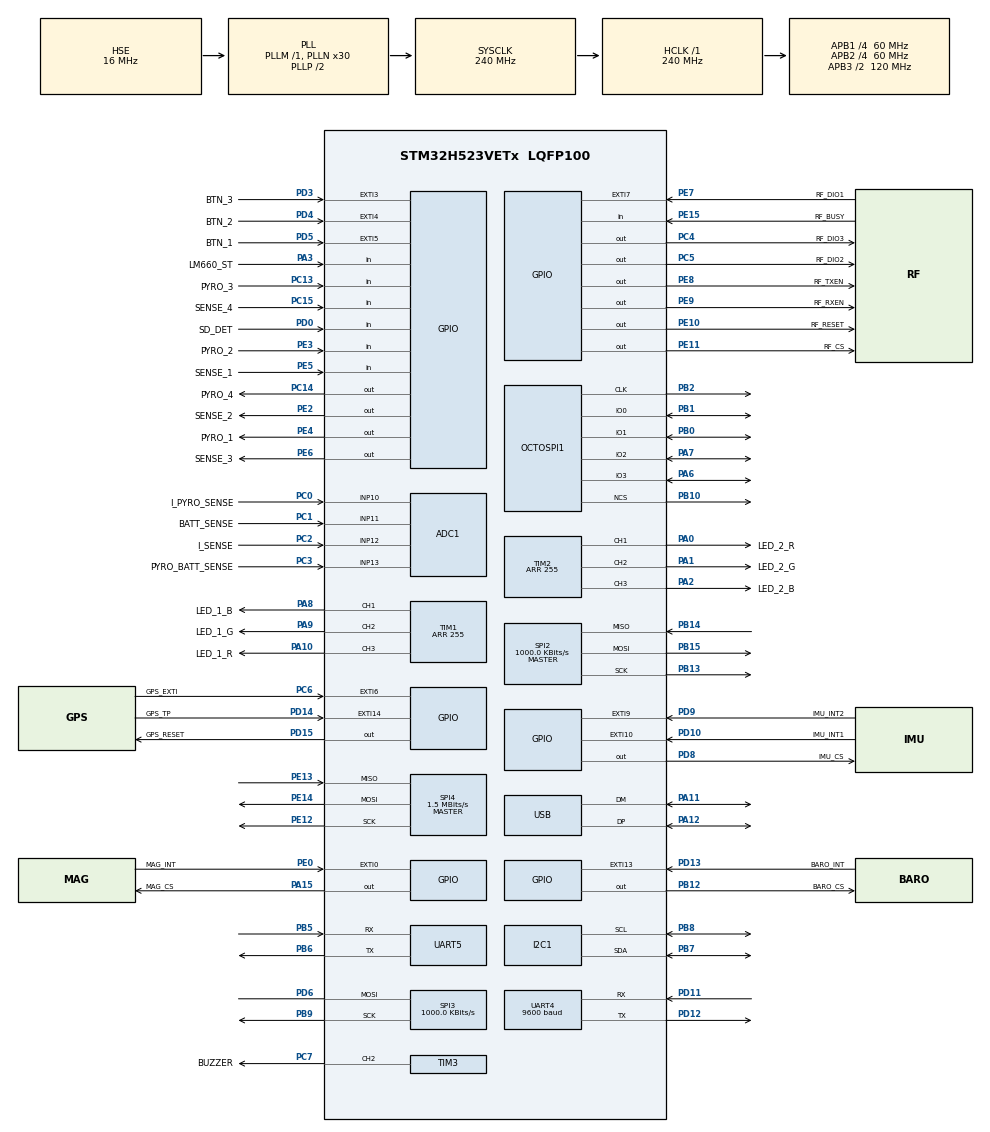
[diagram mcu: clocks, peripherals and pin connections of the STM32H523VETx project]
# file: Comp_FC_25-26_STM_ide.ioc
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ADC1.Channel-1\#ChannelRegularConversion=ADC_CHANNEL_10
ADC1.MonitoredBy-1\#ChannelRegularConversion=__NULL
ADC1.NbrOfConversion=1
ADC1.NbrOfConversionFlag=1
ADC1.OffsetNumber-1\#ChannelRegularConversion=ADC_OFFSET_NONE
ADC1.Rank-1\#ChannelRegularConversion=1
ADC1.SamplingTime-1\#ChannelRegularConversion=ADC_SAMPLETIME_2CYCLES_5
ADC1.master=1
BOOTPATH.BootPathName=LEGACY
BOOTPATH.UserSelectedBootPath=LEGACY
CORTEX_M33_NS.userName=CORTEX_M33
GPDMA1.DESTINC_GPDMACH0=DMA_DINC_INCREMENTED
GPDMA1.DESTINC_GPDMACH4=DMA_DINC_INCREMENTED
GPDMA1.DESTINC_GPDMACH5=DMA_DINC_INCREMENTED
GPDMA1.DIRECTION_GPDMACH1=DMA_MEMORY_TO_PERIPH
GPDMA1.DMAHANDLE_GPDMACH5=hdmatx
GPDMA1.IPHANDLE_GPDMACH0-SIMPLEREQUEST_GPDMACH0=__NULL
GPDMA1.IPHANDLE_GPDMACH1-SIMPLEREQUEST_GPDMACH1=__NULL
GPDMA1.IPHANDLE_GPDMACH4-SIMPLEREQUEST_GPDMACH4=__NULL
GPDMA1.IPHANDLE_GPDMACH5-SIMPLEREQUEST_GPDMACH5=__NULL
GPDMA1.REQUEST_GPDMACH0=GPDMA1_REQUEST_SPI2_RX
GPDMA1.REQUEST_GPDMACH1=GPDMA1_REQUEST_SPI2_TX
GPDMA1.REQUEST_GPDMACH4=GPDMA1_REQUEST_OCTOSPI1
GPDMA1.REQUEST_GPDMACH5=GPDMA1_REQUEST_OCTOSPI1
GPDMA1.SRCINC_GPDMACH1=DMA_SINC_INCREMENTED
GPDMA1.TRANSFERALLOCATEDPORTDEST_GPDMACH0=DMA_DEST_ALLOCATED_PORT1
GPDMA1.TRANSFERALLOCATEDPORTDEST_GPDMACH5=DMA_DEST_ALLOCATED_PORT1
GPDMA1.TRANSFERALLOCATEDPORTSRC_GPDMACH0=DMA_SRC_ALLOCATED_PORT1
GPDMA1.TRANSFERALLOCATEDPORTSRC_GPDMACH4=DMA_SRC_ALLOCATED_PORT1
GPDMA2.CIRCULARMODE_GPDMACH4=DISABLE
GPDMA2.CIRCULARMODE_GPDMACH5=ENABLE
GPDMA2.DESTINC_GPDMACH5=DMA_DINC_INCREMENTED
GPDMA2.DIRECTION_GPDMACH4=DMA_MEMORY_TO_PERIPH
GPDMA2.IPHANDLE_GPDMACH4-SIMPLEREQUEST_GPDMACH4=__NULL
GPDMA2.IPHANDLE_GPDMACH5-SIMPLEREQUEST_GPDMACH5=__NULL
GPDMA2.LINKALLOCATEDPORT_CIRCULAR_GPDMACH5=DMA_LINK_ALLOCATED_PORT1
GPDMA2.REQUEST_GPDMACH4=GPDMA2_REQUEST_UART4_TX
GPDMA2.REQUEST_GPDMACH5=GPDMA2_REQUEST_UART4_RX
GPDMA2.SRCINC_GPDMACH4=DMA_SINC_INCREMENTED
GPDMA2.TRANSFERALLOCATEDPORTDEST_GPDMACH5=DMA_DEST_ALLOCATED_PORT1
GPDMA2.TRANSFERALLOCATEDPORTSRC_GPDMACH5=DMA_SRC_ALLOCATED_PORT1
I2C1.Timing=0x20303E5D
Mcu.Family=STM32H5
Mcu.Name=STM32H523VETx
Mcu.Package=LQFP100
NVIC.EXTI10_IRQn=true\:0\:0\:false\:false\:true\:true\:true\:true
NVIC.EXTI13_IRQn=true\:0\:0\:false\:false\:true\:true\:true\:true
NVIC.EXTI3_IRQn=true\:0\:0\:false\:false\:true\:true\:true\:true
NVIC.EXTI4_IRQn=true\:0\:0\:false\:false\:true\:true\:true\:true
NVIC.EXTI5_IRQn=true\:0\:0\:false\:false\:true\:true\:true\:true
NVIC.EXTI7_IRQn=true\:0\:0\:false\:false\:true\:true\:true\:true
NVIC.EXTI9_IRQn=true\:0\:0\:false\:false\:true\:true\:true\:true
NVIC.GPDMA1_Channel0_IRQn=true\:0\:0\:false\:false\:true\:true\:true\:true
NVIC.GPDMA1_Channel1_IRQn=true\:0\:0\:false\:false\:true\:true\:true\:true
NVIC.GPDMA1_Channel4_IRQn=true\:0\:0\:false\:false\:true\:true\:true\:true
NVIC.GPDMA1_Channel5_IRQn=true\:0\:0\:false\:false\:true\:true\:true\:true
NVIC.GPDMA2_Channel4_IRQn=true\:0\:0\:false\:false\:true\:false\:true\:true
NVIC.GPDMA2_Channel5_IRQn=true\:0\:0\:false\:false\:true\:false\:true\:true
NVIC.PriorityGroup=NVIC_PRIORITYGROUP_4
NVIC.SPI2_IRQn=true\:0\:0\:false\:false\:true\:true\:true\:true
NVIC.SPI3_IRQn=true\:0\:0\:false\:false\:true\:true\:true\:true
NVIC.SPI4_IRQn=true\:0\:0\:false\:false\:true\:true\:true\:true
NVIC.TIM6_IRQn=true\:0\:0\:false\:false\:true\:true\:true\:true
OCTOSPI1.ClockMode=HAL_XSPI_CLOCK_MODE_3
OCTOSPI1.ClockPrescaler=1
OCTOSPI1.MemorySize=HAL_XSPI_SIZE_128MB
PA0.GPIO_Label=LED_2_R
PA0.PinAttribute=Free
PA0.Signal=S_TIM2_CH1
PA1.GPIO_Label=LED_2_G
PA1.PinAttribute=Free
PA1.Signal=S_TIM2_CH2
PA10.GPIO_Label=LED_1_R
PA10.PinAttribute=Free
PA10.Signal=S_TIM1_CH3
PA11.Mode=Device
PA11.Signal=USB_DM
PA12.Mode=Device
PA12.Signal=USB_DP
PA13(JTMS/SWDIO).Mode=Trace_Asynchronous_SW
PA13(JTMS/SWDIO).Signal=DEBUG_JTMS-SWDIO
PA14(JTCK/SWCLK).Mode=Trace_Asynchronous_SW
PA14(JTCK/SWCLK).Signal=DEBUG_JTCK-SWCLK
PA15(JTDI).GPIO_Label=MAG_CS
PA15(JTDI).GPIO_PuPd=GPIO_PULLUP
PA15(JTDI).PinState=GPIO_PIN_RESET
PA15(JTDI).Signal=GPIO_Output
PA2.GPIO_Label=LED_2_B
PA2.PinAttribute=Free
PA2.Signal=S_TIM2_CH3
PA3.GPIO_Label=LM660_ST
PA3.PinAttribute=Free
PA3.Signal=GPIO_Input
PA6.Mode=OCTOSPI1_IO[3\:0]
PA6.PinAttribute=Free
PA6.Signal=OCTOSPI1_IO3
PA7.Mode=OCTOSPI1_IO[3\:0]
PA7.PinAttribute=Free
PA7.Signal=OCTOSPI1_IO2
PA8.GPIO_Label=LED_1_B
PA8.Signal=S_TIM1_CH1
PA9.GPIO_Label=LED_1_G
PA9.PinAttribute=Free
PA9.Signal=S_TIM1_CH2
PB0.Mode=OCTOSPI1_IO[3\:0]
PB0.PinAttribute=Free
PB0.Signal=OCTOSPI1_IO1
PB1.Mode=OCTOSPI1_IO[3\:0]
PB1.PinAttribute=Free
PB1.Signal=OCTOSPI1_IO0
PB10.Mode=quad_mode
PB10.PinAttribute=Free
PB10.Signal=OCTOSPI1_NCS
PB12.GPIO_Label=BARO_CS
PB12.GPIO_PuPd=GPIO_PULLUP
PB12.PinAttribute=Free
PB12.Signal=GPIO_Output
PB13.Mode=Full_Duplex_Master
PB13.PinAttribute=Free
PB13.Signal=SPI2_SCK
PB14.Mode=Full_Duplex_Master
PB14.PinAttribute=Free
PB14.Signal=SPI2_MISO
PB15.Mode=Full_Duplex_Master
PB15.PinAttribute=Free
PB15.Signal=SPI2_MOSI
PB2.Mode=quad_mode
PB2.PinAttribute=Free
PB2.Signal=OCTOSPI1_CLK
PB3(JTDO/TRACESWO).Mode=Trace_Asynchronous_SW
PB3(JTDO/TRACESWO).Signal=DEBUG_JTDO-SWO
PB5.Mode=Asynchronous
PB5.PinAttribute=Free
PB5.Signal=UART5_RX
PB6.Mode=Asynchronous
PB6.PinAttribute=Free
PB6.Signal=UART5_TX
PB7.Mode=I2C
PB7.PinAttribute=Free
PB7.Signal=I2C1_SDA
PB8.Mode=I2C
PB8.PinAttribute=Free
PB8.Signal=I2C1_SCL
PB9.Mode=Simplex_Bidirectional_Master
PB9.PinAttribute=Free
PB9.Signal=SPI3_SCK
PC0.GPIO_Label=I_PYRO_SENSE
PC0.PinAttribute=Free
PC0.Signal=ADCx_INP10
PC1.GPIO_Label=BATT_SENSE
PC1.PinAttribute=Free
PC1.Signal=ADCx_INP11
PC10.PinAttribute=Free
PC10.Signal=SDMMC1_D2
PC11.PinAttribute=Free
PC11.Signal=SDMMC1_D3
PC12.PinAttribute=Free
PC12.Signal=SDMMC1_CK
PC13.GPIO_Label=PYRO_3
PC13.PinAttribute=Free
PC13.Signal=GPIO_Input
PC14-OSC32_IN(OSC32_IN).GPIO_Label=PYRO_4
PC14-OSC32_IN(OSC32_IN).PinAttribute=Free
PC14-OSC32_IN(OSC32_IN).Signal=GPIO_Output
PC15-OSC32_OUT(OSC32_OUT).GPIO_Label=SENSE_4
PC15-OSC32_OUT(OSC32_OUT).PinAttribute=Free
PC15-OSC32_OUT(OSC32_OUT).Signal=GPIO_Input
PC2.GPIO_Label=I_SENSE
PC2.PinAttribute=Free
PC2.Signal=ADCx_INP12
PC3.GPIO_Label=PYRO_BATT_SENSE
PC3.PinAttribute=Free
PC3.Signal=ADCx_INP13
PC4.GPIO_Label=RF_DIO3
PC4.PinAttribute=Free
PC4.Signal=GPIO_Output
PC5.GPIO_Label=RF_DIO2
PC5.PinAttribute=Free
PC5.Signal=GPIO_Output
PC6.GPIO_Label=GPS_EXTI
PC6.PinAttribute=Free
PC6.Signal=GPXTI6
PC7.GPIO_Label=BUZZER
PC7.PinAttribute=Free
PC7.Signal=S_TIM3_CH2
PC8.PinAttribute=Free
PC8.Signal=SDMMC1_D0
PC9.PinAttribute=Free
PC9.Signal=SDMMC1_D1
PD0.GPIO_Label=SD_DET
PD0.PinAttribute=Free
PD0.Signal=GPIO_Input
PD10.GPIO_Label=IMU_INT1
PD10.GPIO_PuPd=GPIO_PULLDOWN
PD10.PinAttribute=Free
PD10.Signal=GPXTI10
PD11.Mode=Asynchronous
PD11.PinAttribute=Free
PD11.Signal=UART4_RX
PD12.Mode=Asynchronous
PD12.PinAttribute=Free
PD12.Signal=UART4_TX
PD13.GPIO_Label=BARO_INT
PD13.GPIO_ModeDefaultEXTI=GPIO_MODE_IT_RISING
PD13.GPIO_PuPd=GPIO_NOPULL
PD13.Signal=GPXTI13
PD14.GPIO_Label=GPS_TP
PD14.PinAttribute=Free
PD14.Signal=GPXTI14
PD15.GPIO_Label=GPS_RESET
PD15.PinAttribute=Free
PD15.Signal=GPIO_Output
PD2.PinAttribute=Free
PD2.Signal=SDMMC1_CMD
PD3.GPIO_Label=BTN_3
PD3.GPIO_PuPd=GPIO_PULLDOWN
PD3.PinAttribute=Free
PD3.Signal=GPXTI3
PD4.GPIO_Label=BTN_2
PD4.GPIO_PuPd=GPIO_PULLDOWN
PD4.PinAttribute=Free
PD4.Signal=GPXTI4
PD5.GPIO_Label=BTN_1
PD5.GPIO_PuPd=GPIO_PULLDOWN
PD5.PinAttribute=Free
PD5.Signal=GPXTI5
PD6.Mode=Simplex_Bidirectional_Master
PD6.PinAttribute=Free
PD6.Signal=SPI3_MOSI
PD8.GPIO_Label=IMU_CS
PD8.GPIO_PuPd=GPIO_PULLUP
PD8.PinAttribute=Free
PD8.Signal=GPIO_Output
PD9.GPIO_Label=IMU_INT2
PD9.GPIO_PuPd=GPIO_PULLDOWN
PD9.PinAttribute=Free
PD9.Signal=GPXTI9
PE0.GPIO_Label=MAG_INT
PE0.PinAttribute=Free
PE0.Signal=GPXTI0
PE10.GPIO_Label=RF_RESET
PE10.PinAttribute=Free
PE10.Signal=GPIO_Output
PE11.GPIO_Label=RF_CS
PE11.GPIO_PuPd=GPIO_PULLUP
PE11.Signal=GPIO_Output
PE12.Mode=Full_Duplex_Master
PE12.PinAttribute=Free
PE12.Signal=SPI4_SCK
PE13.Mode=Full_Duplex_Master
PE13.PinAttribute=Free
PE13.Signal=SPI4_MISO
PE14.Mode=Full_Duplex_Master
PE14.PinAttribute=Free
PE14.Signal=SPI4_MOSI
PE15.GPIO_Label=RF_BUSY
PE15.GPIO_PuPd=GPIO_PULLDOWN
PE15.Signal=GPIO_Input
PE2.GPIO_Label=SENSE_2
PE2.PinAttribute=Free
PE2.Signal=GPIO_Output
PE3.GPIO_Label=PYRO_2
PE3.PinAttribute=Free
PE3.Signal=GPIO_Input
PE4.GPIO_Label=PYRO_1
PE4.PinAttribute=Free
PE4.Signal=GPIO_Output
PE5.GPIO_Label=SENSE_1
PE5.PinAttribute=Free
PE5.Signal=GPIO_Input
PE6.GPIO_Label=SENSE_3
PE6.PinAttribute=Free
PE6.Signal=GPIO_Output
PE7.GPIO_Label=RF_DIO1
PE7.Signal=GPXTI7
PE8.GPIO_Label=RF_TXEN
PE8.PinAttribute=Free
PE8.Signal=GPIO_Output
PE9.GPIO_Label=RF_RXEN
PE9.PinAttribute=Free
PE9.Signal=GPIO_Output
PH0-OSC_IN(PH0).Mode=HSE-External-Oscillator
PH0-OSC_IN(PH0).Signal=RCC_OSC_IN
PH1-OSC_OUT(PH1).Mode=HSE-External-Oscillator
PH1-OSC_OUT(PH1).Signal=RCC_OSC_OUT
ProjectManager.HeapSize=0x200
ProjectManager.StackSize=0x400
ProjectManager.TargetToolchain=STM32CubeIDE
RCC.ADCCLockSelection=RCC_ADCDACCLKSOURCE_PLL2R
RCC.ADCFreq_Value=32000000
RCC.AHBFreq_Value=240000000
RCC.APB1CLKDivider=RCC_HCLK_DIV4
RCC.APB1Freq_Value=60000000
RCC.APB1TimFreq_Value=120000000
RCC.APB2CLKDivider=RCC_HCLK_DIV4
RCC.APB2Freq_Value=60000000
RCC.APB2TimFreq_Value=120000000
RCC.APB3CLKDivider=RCC_HCLK_DIV2
RCC.APB3Freq_Value=120000000
RCC.CSI_VALUE=4000000
RCC.CortexFreq_Value=240000000
RCC.EPOD_VALUE=16000000
RCC.HCLKFreq_Value=240000000
RCC.HSE_VALUE=16000000
RCC.HSI48_VALUE=48000000
RCC.HSI_VALUE=64000000
RCC.I2C1CLockSelection=RCC_I2C1CLKSOURCE_PLL3R
RCC.LSE_VALUE=32768
RCC.LSIRC_VALUE=32000
RCC.PLL1Q=15
RCC.PLL2FRACN=0
RCC.PLL2N=8
RCC.PLL2P=8
RCC.PLL2Q=4
RCC.PLL2R=4
RCC.PLL2Source=RCC_PLL2_SOURCE_HSE
RCC.PLL3FRACN=0
RCC.PLL3N=15
RCC.PLL3Q=5
RCC.PLL3R=5
RCC.PLL3Source=RCC_PLL3_SOURCE_HSE
RCC.PLLFRACN=0
RCC.PLLN=30
RCC.PLLSourceVirtual=RCC_PLL1_SOURCE_HSE
RCC.SPI4CLockSelection=RCC_SPI4CLKSOURCE_PLL3Q
RCC.SYSCLKFreq_VALUE=240000000
RCC.SYSCLKSource=RCC_SYSCLKSOURCE_PLLCLK
RCC.UART4CLockSelection=RCC_UART4CLKSOURCE_PLL2Q
RCC.UART5CLockSelection=RCC_UART5CLKSOURCE_PLL2Q
RCC.USBCLockSelection=RCC_USBCLKSOURCE_PLL3Q
RCC.USBFreq_Value=48000000
RCC.VCOOutputFreq_Value=480000000
SH.ADCx_INP10.0=ADC1_INP10,IN10-Single-Ended
SH.ADCx_INP11.0=ADC1_INP11,IN11-Single-Ended
SH.ADCx_INP12.0=ADC1_INP12,IN12-Single-Ended
SH.ADCx_INP13.0=ADC1_INP13,IN13-Single-Ended
SH.S_TIM1_CH1.0=TIM1_CH1,PWM Generation1 CH1
SH.S_TIM1_CH2.0=TIM1_CH2,PWM Generation2 CH2
SH.S_TIM1_CH3.0=TIM1_CH3,PWM Generation3 CH3
SH.S_TIM2_CH1.0=TIM2_CH1,PWM Generation1 CH1
SH.S_TIM2_CH2.0=TIM2_CH2,PWM Generation2 CH2
SH.S_TIM2_CH3.0=TIM2_CH3,PWM Generation3 CH3
SH.S_TIM3_CH2.0=TIM3_CH2,PWM Generation2 CH2
SPI2.BaudRatePrescaler=SPI_BAUDRATEPRESCALER_32
SPI2.CLKPhase=SPI_PHASE_2EDGE
SPI2.CLKPolarity=SPI_POLARITY_HIGH
SPI2.CalculateBaudRate=1000.0 KBits/s
SPI2.DataSize=SPI_DATASIZE_8BIT
SPI2.Direction=SPI_DIRECTION_2LINES
SPI2.MasterKeepIOState=SPI_MASTER_KEEP_IO_STATE_ENABLE
SPI2.Mode=SPI_MODE_MASTER
SPI2.VirtualType=VM_MASTER
SPI3.BaudRatePrescaler=SPI_BAUDRATEPRESCALER_32
SPI3.CLKPhase=SPI_PHASE_2EDGE
SPI3.CLKPolarity=SPI_POLARITY_HIGH
SPI3.CalculateBaudRate=1000.0 KBits/s
SPI3.DataSize=SPI_DATASIZE_8BIT
SPI3.Direction=SPI_DIRECTION_1LINE
SPI3.Mode=SPI_MODE_MASTER
SPI3.VirtualType=VM_MASTER
SPI4.BaudRatePrescaler=SPI_BAUDRATEPRESCALER_32
SPI4.CLKPhase=SPI_PHASE_1EDGE
SPI4.CLKPolarity=SPI_POLARITY_LOW
SPI4.CalculateBaudRate=1.5 MBits/s
SPI4.DataSize=SPI_DATASIZE_8BIT
SPI4.Direction=SPI_DIRECTION_2LINES
SPI4.Mode=SPI_MODE_MASTER
SPI4.VirtualType=VM_MASTER
TIM1.Channel-PWM\ Generation1\ CH1=TIM_CHANNEL_1
TIM1.Channel-PWM\ Generation2\ CH2=TIM_CHANNEL_2
TIM1.Channel-PWM\ Generation3\ CH3=TIM_CHANNEL_3
TIM1.PeriodNoDither=255
TIM2.Channel-PWM\ Generation1\ CH1=TIM_CHANNEL_1
TIM2.Channel-PWM\ Generation2\ CH2=TIM_CHANNEL_2
TIM2.Channel-PWM\ Generation3\ CH3=TIM_CHANNEL_3
TIM2.PeriodNoDither=255
TIM3.Channel-PWM\ Generation2\ CH2=TIM_CHANNEL_2
TIM3.PeriodNoDither=43939
TIM3.Prescaler=0
TIM6.PeriodNoDither=9999
TIM6.Prescaler=1199
UART4.BaudRate=9600
USB.VirtualMode=Device_Only
VP_BOOTPATH_VS_BOOTPATH.Mode=BP_Activate
VP_CORTEX_M33_NS_VS_Hclk.Mode=Hclk_Mode
VP_GPDMA1_VS_GPDMACH0.Mode=SIMPLEREQUEST_GPDMACH0
VP_GPDMA1_VS_GPDMACH1.Mode=SIMPLEREQUEST_GPDMACH1
VP_GPDMA1_VS_GPDMACH4.Mode=SIMPLEREQUEST_GPDMACH4
VP_GPDMA1_VS_GPDMACH5.Mode=SIMPLEREQUEST_GPDMACH5
VP_GPDMA2_VS_GPDMACH4.Mode=SIMPLEREQUEST_GPDMACH4
VP_GPDMA2_VS_GPDMACH5.Mode=SIMPLEREQUEST_GPDMACH5
VP_MEMORYMAP_VS_MEMORYMAP.Mode=CurAppReg
VP_PWR_VS_LPOM.Mode=PowerOptimisation
VP_PWR_VS_SECSignals.Mode=Security/Privilege
VP_TIM1_VS_ClockSourceINT.Mode=Internal
VP_TIM2_VS_ClockSourceINT.Mode=Internal
VP_TIM3_VS_ClockSourceINT.Mode=Internal
VP_TIM6_VS_ClockSourceINT.Mode=Enable_Timer
board=custom

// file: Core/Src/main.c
/* USER CODE BEGIN Header */
/**
  ******************************************************************************
  * @file           : main.c
  * @brief          : Main program body
  ******************************************************************************
  * @attention
  *
  * Copyright (c) 2026 STMicroelectronics.
  * All rights reserved.
  *
  * This software is licensed under terms that can be found in the LICENSE file
  * in the root directory of this software component.
  * If no LICENSE file comes with this software, it is provided AS-IS.
  *
  ******************************************************************************
  */
/* USER CODE END Header */
#include "main.h"

/* USER CODE BEGIN Includes */

#include "sensors.h"
#include "rgb_led.h"
#include "buzzer.h"
#include "lora_telemetry.h"
#include <GNSS.h>
#include "packets.h"
#include "flash.h"
#include "btn.h"
#include "mode_handler.h"

#include <string.h>
#include <stdio.h>

/* USER CODE END Includes */

ADC_HandleTypeDef hadc1;

I2C_HandleTypeDef hi2c1;

XSPI_HandleTypeDef hxspi1;
DMA_HandleTypeDef handle_GPDMA1_Channel5;
DMA_HandleTypeDef handle_GPDMA1_Channel4;

SPI_HandleTypeDef hspi2;
SPI_HandleTypeDef hspi3;
SPI_HandleTypeDef hspi4;
DMA_HandleTypeDef handle_GPDMA1_Channel1;
DMA_HandleTypeDef handle_GPDMA1_Channel0;

TIM_HandleTypeDef htim1;
TIM_HandleTypeDef htim2;
TIM_HandleTypeDef htim3;
TIM_HandleTypeDef htim6;

UART_HandleTypeDef huart4;
UART_HandleTypeDef huart5;
DMA_NodeTypeDef Node_GPDMA2_Channel5;
DMA_QListTypeDef List_GPDMA2_Channel5;
DMA_HandleTypeDef handle_GPDMA2_Channel5;
DMA_HandleTypeDef handle_GPDMA2_Channel4;

PCD_HandleTypeDef hpcd_USB_DRD_FS;

/* USER CODE BEGIN PV */
rgb_led_t led1 = {
    .handle = &htim1,
    .channel_r = TIM_CHANNEL_3,
    .channel_g = TIM_CHANNEL_2,
    .channel_b = TIM_CHANNEL_1
};
rgb_led_t led2 = {
    .handle = &htim2,
    .channel_r = TIM_CHANNEL_1,
    .channel_g = TIM_CHANNEL_2,
    .channel_b = TIM_CHANNEL_3
};
buzzer_t buzzer = {
    .handle = &htim3,
	.channel_buz = TIM_CHANNEL_2
};

flash_t flash = {
    .hxspi = &hxspi1,
    .address = 0,
    .full = 0,
    .prescaler_max = 10, // default to 10 hz for waiting on pad
    .prescaler_cnt = 0
};

sx126x_ctx_t radio = {
    // GPIO Ports and Pins
      //pointer to spi class
	.hspi = &hspi4,
    .device = FLIGHT_COMPUTER,
};

btn_t btns[3];

// Control system tick
uint8_t poll = 1;
uint8_t tick_100Hz = 0;

extern uint8_t baro_ready;
extern uint8_t mag_ready;
extern uint8_t imu_ready;

// Global state
state_t global_state = {0};

/* USER CODE END PV */

void SystemClock_Config(void);
void PeriphCommonClock_Config(void);
static void MX_GPIO_Init(void);
static void MX_GPDMA1_Init(void);
static void MX_GPDMA2_Init(void);
static void MX_OCTOSPI1_Init(void);
static void MX_SPI3_Init(void);
static void MX_UART4_Init(void);
static void MX_USB_PCD_Init(void);
static void MX_SPI2_Init(void);
static void MX_SPI4_Init(void);
static void MX_UART5_Init(void);
static void MX_ADC1_Init(void);
static void MX_I2C1_Init(void);
static void MX_TIM1_Init(void);
static void MX_TIM2_Init(void);
static void MX_TIM6_Init(void);
static void MX_TIM3_Init(void);
/* USER CODE BEGIN PFP */
// printf UART
#define PUTCHAR_PROTOTYPE int __io_putchar(int ch)

int32_t platform_write(void *handle, uint8_t reg, const uint8_t *bufp, uint16_t len, uint8_t device);
int32_t platform_read(void *handle, uint8_t reg, uint8_t *bufp, uint16_t len, uint8_t device);
void platform_delay(uint32_t millisec);

/* USER CODE END PFP */

int main(void)
{

  /* MCU Configuration--------------------------------------------------------*/

  /* Reset of all peripherals, Initializes the Flash interface and the Systick. */
  HAL_Init();

  /* Configure the system clock */
  SystemClock_Config();

  /* Configure the peripherals common clocks */
  PeriphCommonClock_Config();

  /* Initialize all configured peripherals */
  MX_GPIO_Init();
  MX_GPDMA1_Init();
  MX_GPDMA2_Init();
  MX_OCTOSPI1_Init();
  MX_SPI3_Init();
  MX_UART4_Init();
  MX_USB_PCD_Init();
  MX_SPI2_Init();
  MX_SPI4_Init();
  MX_UART5_Init();
  MX_ADC1_Init();
  MX_I2C1_Init();
  MX_TIM1_Init();
  MX_TIM2_Init();
  MX_TIM6_Init();
  MX_TIM3_Init();
  /* USER CODE BEGIN 2 */

  rgb_led_init(&led1);
  rgb_led_init(&led2);
  rgb_led_set(&led1, 0x800000);
  rgb_led_set(&led2, 0x000080);

  HAL_TIM_Base_Start_IT(&htim6); // start 100 Hz

  buzzer_init(&buzzer);

  //toggle cs_pins
  HAL_Delay(100);
  HAL_GPIO_WritePin(BARO_CS_GPIO_Port, BARO_CS_Pin, 0);
  HAL_Delay(100);
  HAL_GPIO_WritePin(BARO_CS_GPIO_Port, BARO_CS_Pin, 1);
  HAL_Delay(100);

  HAL_Delay(100);
  HAL_GPIO_WritePin(IMU_CS_GPIO_Port, IMU_CS_Pin, 0);
  HAL_Delay(100);
  HAL_GPIO_WritePin(IMU_CS_GPIO_Port, IMU_CS_Pin, 1);
  HAL_Delay(100);

printf("Hello, world!\r\n");
HAL_Delay(100);

LoRa_init(&radio);
sensors_init();
HAL_Delay(100);

btn_init(&btns[0], BTN_1_GPIO_Port, BTN_1_Pin);
btn_init(&btns[1], BTN_2_GPIO_Port, BTN_2_Pin);
btn_init(&btns[2], BTN_3_GPIO_Port, BTN_3_Pin);

GNSS_Init(&GNSS_Handle, &huart4);
HAL_Delay(1000);
GNSS_LoadConfig(&GNSS_Handle);

			GNSS_GetUniqID(&GNSS_Handle);
			GNSS_ParseBuffer(&GNSS_Handle);
			HAL_Delay(250);
			GNSS_GetPVTData(&GNSS_Handle);
			GNSS_ParseBuffer(&GNSS_Handle);

 		  HAL_Delay(250);
 		 				printf("Day: %d-%d-%d \r\n", GNSS_Handle.day, GNSS_Handle.month,GNSS_Handle.year);
 		 				printf("Time: %d:%d:%d \r\n", GNSS_Handle.hour, GNSS_Handle.min,GNSS_Handle.sec);
 		 				printf("Status of fix: %d \r\n", GNSS_Handle.fixType);
 		 				printf("Latitude: %d \r\n", GNSS_Handle.fLat);
 		 				printf("Longitude: %d \r\n", GNSS_Handle.lon / 10000000);
 		 				printf("Height above ellipsoid: %d \r\n", GNSS_Handle.height);
 		 				printf("Height above mean sea level: %d \r\n", GNSS_Handle.hMSL);
 		 				printf("Ground Speed (2-D): %d \r\n", GNSS_Handle.gSpeed);
 		 				printf("Unique ID: %04X %04X %04X %04X %04X \n\r",

 		 						GNSS_Handle.uniqueID[0], GNSS_Handle.uniqueID[1],
 		 						GNSS_Handle.uniqueID[2], GNSS_Handle.uniqueID[3],
 		 						GNSS_Handle.uniqueID[4], GNSS_Handle.uniqueID[5]);

 		 				global_state.gps_lat = GNSS_Handle.fLat;
 		 				global_state.gps_long = GNSS_Handle.lon;

  /* USER CODE END 2 */

  /* Infinite loop */
  /* USER CODE BEGIN WHILE */
  while (1)
  {

//	  if (HAL_GPIO_ReadPin(BTN_1_GPIO_Port, BTN_1_Pin) == 1){
//		  buzzer_set(&buzzer, 1);
//		  HAL_GPIO_WritePin(PYRO_1_GPIO_Port, PYRO_1_Pin, 0);
//		  HAL_GPIO_WritePin(PYRO_2_GPIO_Port, PYRO_2_Pin, 1);
//		  HAL_GPIO_WritePin(PYRO_3_GPIO_Port, PYRO_3_Pin, 1);
//		  HAL_GPIO_WritePin(PYRO_4_GPIO_Port, PYRO_4_Pin, 0);
//	  } else { buzzer_set(&buzzer, 0);
//	  HAL_GPIO_WritePin(PYRO_1_GPIO_Port, PYRO_1_Pin, 0);
//	  HAL_GPIO_WritePin(PYRO_2_GPIO_Port, PYRO_2_Pin, 0);
//	  HAL_GPIO_WritePin(PYRO_3_GPIO_Port, PYRO_3_Pin, 0);
//	  HAL_GPIO_WritePin(PYRO_4_GPIO_Port, PYRO_4_Pin, 0);
//	  }

//	  HAL_GPIO_WritePin(PYRO_2_GPIO_Port, PYRO_2_Pin, 1);

	  if (tick_100Hz) {
	  		  tick_100Hz = 0;

	  		  	  	  btn_update(&btns[0]);
	  				  btn_update(&btns[1]);
	  				  btn_update(&btns[2]);

	  				if (btn_get_edge(&btns[0]) == 1)
	  							{
	  								printf("btn 1 pressed\r\n");

	  							};

	  				 if (btn_get_edge(&btns[1]) == 1)
	  					  							{
	  					  			printf("btn 2 pressed\r\n");

	  					  							};

	  			if (btn_get_edge(&btns[2]) == 1)
	  					  							{
	  					  			printf("btn 3 pressed\r\n");

	  					  							};

	  			if (btn_get_edge(&btns[1]) == -1)
	  							{
	  					printf("btn 2 released\r\n");
	  							};
	  float pres;

	  float accel;
//	 	 	  		get_accel_ms2(&accel);
//	 	 	  		printf("Acceleration:, %f\r\n", accel);
//
//
//	 float omega;
//	 	 	 	 	 get_omega_rads(&omega);
//	 	 	  		printf("Omega:, %f\r\n", omega);
//
//
//	 	 	 	 	 get_pres_hpa(&pres);
//	 	 	 	  		printf("Pressure:, %f\r\n", pres);

	 	 	 	  	static uint8_t counter = 0 ;
	 	 	 	  				 if (counter%100 == 0){
	 	 	 	  					 telemetry_tx_string("Hello World", &radio);
	 	 	 	  					 counter = 0 ;
	 	 	 	  				 }
	 	 	 	  		 	 counter++;

	  }

	 	  		//detect launch (LAUNCH_DETECT)
	 	  		// if launch detect == 1 and apogee detect == 0, then ascent

	 	  		//if launch is detected, then start polling for apogee after motor burnout (APOGEE_DETECT)
	 	  		// if launch detect == 1 and apogee detect == 1, then descent

	 	  		//landing detect
	 	  		// if launch detect == 1, apogee detect = 1, start polling for landing

	  //TODO
	  //modes
	  //telemetry
	  //check lora packet status

	  };
    /* USER CODE END WHILE */

}

void SystemClock_Config(void)
{
  RCC_OscInitTypeDef RCC_OscInitStruct = {0};
  RCC_ClkInitTypeDef RCC_ClkInitStruct = {0};

  /** Configure the main internal regulator output voltage
  */
  __HAL_PWR_VOLTAGESCALING_CONFIG(PWR_REGULATOR_VOLTAGE_SCALE0);

  while(!__HAL_PWR_GET_FLAG(PWR_FLAG_VOSRDY)) {}

  /** Initializes the RCC Oscillators according to the specified parameters
  * in the RCC_OscInitTypeDef structure.
  */
  RCC_OscInitStruct.OscillatorType = RCC_OSCILLATORTYPE_HSE;
  RCC_OscInitStruct.HSEState = RCC_HSE_ON;
  RCC_OscInitStruct.PLL.PLLState = RCC_PLL_ON;
  RCC_OscInitStruct.PLL.PLLSource = RCC_PLL1_SOURCE_HSE;
  RCC_OscInitStruct.PLL.PLLM = 1;
  RCC_OscInitStruct.PLL.PLLN = 30;
  RCC_OscInitStruct.PLL.PLLP = 2;
  RCC_OscInitStruct.PLL.PLLQ = 15;
  RCC_OscInitStruct.PLL.PLLR = 2;
  RCC_OscInitStruct.PLL.PLLRGE = RCC_PLL1_VCIRANGE_3;
  RCC_OscInitStruct.PLL.PLLVCOSEL = RCC_PLL1_VCORANGE_WIDE;
  RCC_OscInitStruct.PLL.PLLFRACN = 0;
  if (HAL_RCC_OscConfig(&RCC_OscInitStruct) != HAL_OK)
  {
    Error_Handler();
  }

  /** Initializes the CPU, AHB and APB buses clocks
  */
  RCC_ClkInitStruct.ClockType = RCC_CLOCKTYPE_HCLK|RCC_CLOCKTYPE_SYSCLK
                              |RCC_CLOCKTYPE_PCLK1|RCC_CLOCKTYPE_PCLK2
                              |RCC_CLOCKTYPE_PCLK3;
  RCC_ClkInitStruct.SYSCLKSource = RCC_SYSCLKSOURCE_PLLCLK;
  RCC_ClkInitStruct.AHBCLKDivider = RCC_SYSCLK_DIV1;
  RCC_ClkInitStruct.APB1CLKDivider = RCC_HCLK_DIV4;
  RCC_ClkInitStruct.APB2CLKDivider = RCC_HCLK_DIV4;
  RCC_ClkInitStruct.APB3CLKDivider = RCC_HCLK_DIV2;

  if (HAL_RCC_ClockConfig(&RCC_ClkInitStruct, FLASH_LATENCY_5) != HAL_OK)
  {
    Error_Handler();
  }

  /** Configure the programming delay
  */
  __HAL_FLASH_SET_PROGRAM_DELAY(FLASH_PROGRAMMING_DELAY_2);
}

void PeriphCommonClock_Config(void)
{
  RCC_PeriphCLKInitTypeDef PeriphClkInitStruct = {0};

  /** Initializes the peripherals clock
  */
  PeriphClkInitStruct.PeriphClockSelection = RCC_PERIPHCLK_USB|RCC_PERIPHCLK_ADCDAC
                              |RCC_PERIPHCLK_UART4|RCC_PERIPHCLK_UART5
                              |RCC_PERIPHCLK_I2C1|RCC_PERIPHCLK_SPI4;
  PeriphClkInitStruct.PLL2.PLL2Source = RCC_PLL2_SOURCE_HSE;
  PeriphClkInitStruct.PLL2.PLL2M = 1;
  PeriphClkInitStruct.PLL2.PLL2N = 8;
  PeriphClkInitStruct.PLL2.PLL2P = 8;
  PeriphClkInitStruct.PLL2.PLL2Q = 4;
  PeriphClkInitStruct.PLL2.PLL2R = 4;
  PeriphClkInitStruct.PLL2.PLL2RGE = RCC_PLL2_VCIRANGE_3;
  PeriphClkInitStruct.PLL2.PLL2VCOSEL = RCC_PLL2_VCORANGE_WIDE;
  PeriphClkInitStruct.PLL2.PLL2FRACN = 0;
  PeriphClkInitStruct.PLL2.PLL2ClockOut = RCC_PLL2_DIVQ|RCC_PLL2_DIVR;
  PeriphClkInitStruct.PLL3.PLL3Source = RCC_PLL3_SOURCE_HSE;
  PeriphClkInitStruct.PLL3.PLL3M = 1;
  PeriphClkInitStruct.PLL3.PLL3N = 15;
  PeriphClkInitStruct.PLL3.PLL3P = 2;
  PeriphClkInitStruct.PLL3.PLL3Q = 5;
  PeriphClkInitStruct.PLL3.PLL3R = 5;
  PeriphClkInitStruct.PLL3.PLL3RGE = RCC_PLL3_VCIRANGE_3;
  PeriphClkInitStruct.PLL3.PLL3VCOSEL = RCC_PLL3_VCORANGE_WIDE;
  PeriphClkInitStruct.PLL3.PLL3FRACN = 0;
  PeriphClkInitStruct.PLL3.PLL3ClockOut = RCC_PLL3_DIVR|RCC_PLL3_DIVQ;
  PeriphClkInitStruct.Uart4ClockSelection = RCC_UART4CLKSOURCE_PLL2Q;
  PeriphClkInitStruct.Uart5ClockSelection = RCC_UART5CLKSOURCE_PLL2Q;
  PeriphClkInitStruct.I2c1ClockSelection = RCC_I2C1CLKSOURCE_PLL3R;
  PeriphClkInitStruct.AdcDacClockSelection = RCC_ADCDACCLKSOURCE_PLL2R;
  PeriphClkInitStruct.Spi4ClockSelection = RCC_SPI4CLKSOURCE_PLL3Q;
  PeriphClkInitStruct.UsbClockSelection = RCC_USBCLKSOURCE_PLL3Q;
  if (HAL_RCCEx_PeriphCLKConfig(&PeriphClkInitStruct) != HAL_OK)
  {
    Error_Handler();
  }
}

static void MX_ADC1_Init(void)
{

  ADC_ChannelConfTypeDef sConfig = {0};

  /** Common config
  */
  hadc1.Instance = ADC1;
  hadc1.Init.ClockPrescaler = ADC_CLOCK_ASYNC_DIV1;
  hadc1.Init.Resolution = ADC_RESOLUTION_12B;
  hadc1.Init.DataAlign = ADC_DATAALIGN_RIGHT;
  hadc1.Init.ScanConvMode = ADC_SCAN_DISABLE;
  hadc1.Init.EOCSelection = ADC_EOC_SINGLE_CONV;
  hadc1.Init.LowPowerAutoWait = DISABLE;
  hadc1.Init.ContinuousConvMode = DISABLE;
  hadc1.Init.NbrOfConversion = 1;
  hadc1.Init.DiscontinuousConvMode = DISABLE;
  hadc1.Init.ExternalTrigConv = ADC_SOFTWARE_START;
  hadc1.Init.ExternalTrigConvEdge = ADC_EXTERNALTRIGCONVEDGE_NONE;
  hadc1.Init.DMAContinuousRequests = DISABLE;
  hadc1.Init.SamplingMode = ADC_SAMPLING_MODE_NORMAL;
  hadc1.Init.Overrun = ADC_OVR_DATA_PRESERVED;
  hadc1.Init.OversamplingMode = DISABLE;
  if (HAL_ADC_Init(&hadc1) != HAL_OK)
  {
    Error_Handler();
  }

  /** Configure Regular Channel
  */
  sConfig.Channel = ADC_CHANNEL_10;
  sConfig.Rank = ADC_REGULAR_RANK_1;
  sConfig.SamplingTime = ADC_SAMPLETIME_2CYCLES_5;
  sConfig.SingleDiff = ADC_SINGLE_ENDED;
  sConfig.OffsetNumber = ADC_OFFSET_NONE;
  sConfig.Offset = 0;
  if (HAL_ADC_ConfigChannel(&hadc1, &sConfig) != HAL_OK)
  {
    Error_Handler();
  }

}

static void MX_GPDMA1_Init(void)
{

  /* Peripheral clock enable */
  __HAL_RCC_GPDMA1_CLK_ENABLE();

  /* GPDMA1 interrupt Init */
    HAL_NVIC_SetPriority(GPDMA1_Channel0_IRQn, 0, 0);
    HAL_NVIC_EnableIRQ(GPDMA1_Channel0_IRQn);
    HAL_NVIC_SetPriority(GPDMA1_Channel1_IRQn, 0, 0);
    HAL_NVIC_EnableIRQ(GPDMA1_Channel1_IRQn);
    HAL_NVIC_SetPriority(GPDMA1_Channel4_IRQn, 0, 0);
    HAL_NVIC_EnableIRQ(GPDMA1_Channel4_IRQn);
    HAL_NVIC_SetPriority(GPDMA1_Channel5_IRQn, 0, 0);
    HAL_NVIC_EnableIRQ(GPDMA1_Channel5_IRQn);

}

static void MX_GPDMA2_Init(void)
{

  /* Peripheral clock enable */
  __HAL_RCC_GPDMA2_CLK_ENABLE();

  /* GPDMA2 interrupt Init */
    HAL_NVIC_SetPriority(GPDMA2_Channel4_IRQn, 0, 0);
    HAL_NVIC_EnableIRQ(GPDMA2_Channel4_IRQn);
    HAL_NVIC_SetPriority(GPDMA2_Channel5_IRQn, 0, 0);
    HAL_NVIC_EnableIRQ(GPDMA2_Channel5_IRQn);

}

static void MX_I2C1_Init(void)
{

  hi2c1.Instance = I2C1;
  hi2c1.Init.Timing = 0x20303E5D;
  hi2c1.Init.OwnAddress1 = 0;
  hi2c1.Init.AddressingMode = I2C_ADDRESSINGMODE_7BIT;
  hi2c1.Init.DualAddressMode = I2C_DUALADDRESS_DISABLE;
  hi2c1.Init.OwnAddress2 = 0;
  hi2c1.Init.OwnAddress2Masks = I2C_OA2_NOMASK;
  hi2c1.Init.GeneralCallMode = I2C_GENERALCALL_DISABLE;
  hi2c1.Init.NoStretchMode = I2C_NOSTRETCH_DISABLE;
  if (HAL_I2C_Init(&hi2c1) != HAL_OK)
  {
    Error_Handler();
  }

  /** Configure Analogue filter
  */
  if (HAL_I2CEx_ConfigAnalogFilter(&hi2c1, I2C_ANALOGFILTER_ENABLE) != HAL_OK)
  {
    Error_Handler();
  }

  /** Configure Digital filter
  */
  if (HAL_I2CEx_ConfigDigitalFilter(&hi2c1, 0) != HAL_OK)
  {
    Error_Handler();
  }

}

static void MX_OCTOSPI1_Init(void)
{

  /* OCTOSPI1 parameter configuration*/
  hxspi1.Instance = OCTOSPI1;
  hxspi1.Init.FifoThresholdByte = 1;
  hxspi1.Init.MemoryMode = HAL_XSPI_SINGLE_MEM;
  hxspi1.Init.MemoryType = HAL_XSPI_MEMTYPE_MICRON;
  hxspi1.Init.MemorySize = HAL_XSPI_SIZE_128MB;
  hxspi1.Init.ChipSelectHighTimeCycle = 1;
  hxspi1.Init.FreeRunningClock = HAL_XSPI_FREERUNCLK_DISABLE;
  hxspi1.Init.ClockMode = HAL_XSPI_CLOCK_MODE_3;
  hxspi1.Init.WrapSize = HAL_XSPI_WRAP_NOT_SUPPORTED;
  hxspi1.Init.ClockPrescaler = 1;
  hxspi1.Init.SampleShifting = HAL_XSPI_SAMPLE_SHIFT_NONE;
  hxspi1.Init.DelayHoldQuarterCycle = HAL_XSPI_DHQC_DISABLE;
  hxspi1.Init.ChipSelectBoundary = HAL_XSPI_BONDARYOF_NONE;
  hxspi1.Init.DelayBlockBypass = HAL_XSPI_DELAY_BLOCK_BYPASS;
  hxspi1.Init.Refresh = 0;
  if (HAL_XSPI_Init(&hxspi1) != HAL_OK)
  {
    Error_Handler();
  }

}

static void MX_SPI2_Init(void)
{

  /* SPI2 parameter configuration*/
  hspi2.Instance = SPI2;
  hspi2.Init.Mode = SPI_MODE_MASTER;
  hspi2.Init.Direction = SPI_DIRECTION_2LINES;
  hspi2.Init.DataSize = SPI_DATASIZE_8BIT;
  hspi2.Init.CLKPolarity = SPI_POLARITY_HIGH;
  hspi2.Init.CLKPhase = SPI_PHASE_2EDGE;
  hspi2.Init.NSS = SPI_NSS_SOFT;
  hspi2.Init.BaudRatePrescaler = SPI_BAUDRATEPRESCALER_32;
  hspi2.Init.FirstBit = SPI_FIRSTBIT_MSB;
  hspi2.Init.TIMode = SPI_TIMODE_DISABLE;
  hspi2.Init.CRCCalculation = SPI_CRCCALCULATION_DISABLE;
  hspi2.Init.CRCPolynomial = 0x7;
  hspi2.Init.NSSPMode = SPI_NSS_PULSE_DISABLE;
  hspi2.Init.NSSPolarity = SPI_NSS_POLARITY_LOW;
  hspi2.Init.FifoThreshold = SPI_FIFO_THRESHOLD_01DATA;
  hspi2.Init.MasterSSIdleness = SPI_MASTER_SS_IDLENESS_00CYCLE;
  hspi2.Init.MasterInterDataIdleness = SPI_MASTER_INTERDATA_IDLENESS_00CYCLE;
  hspi2.Init.MasterReceiverAutoSusp = SPI_MASTER_RX_AUTOSUSP_DISABLE;
  hspi2.Init.MasterKeepIOState = SPI_MASTER_KEEP_IO_STATE_ENABLE;
  hspi2.Init.IOSwap = SPI_IO_SWAP_DISABLE;
  hspi2.Init.ReadyMasterManagement = SPI_RDY_MASTER_MANAGEMENT_INTERNALLY;
  hspi2.Init.ReadyPolarity = SPI_RDY_POLARITY_HIGH;
  if (HAL_SPI_Init(&hspi2) != HAL_OK)
  {
    Error_Handler();
  }

}

static void MX_SPI3_Init(void)
{

  /* SPI3 parameter configuration*/
  hspi3.Instance = SPI3;
  hspi3.Init.Mode = SPI_MODE_MASTER;
  hspi3.Init.Direction = SPI_DIRECTION_1LINE;
  hspi3.Init.DataSize = SPI_DATASIZE_8BIT;
  hspi3.Init.CLKPolarity = SPI_POLARITY_HIGH;
  hspi3.Init.CLKPhase = SPI_PHASE_2EDGE;
  hspi3.Init.NSS = SPI_NSS_SOFT;
  hspi3.Init.BaudRatePrescaler = SPI_BAUDRATEPRESCALER_32;
  hspi3.Init.FirstBit = SPI_FIRSTBIT_MSB;
  hspi3.Init.TIMode = SPI_TIMODE_DISABLE;
  hspi3.Init.CRCCalculation = SPI_CRCCALCULATION_DISABLE;
  hspi3.Init.CRCPolynomial = 0x7;
  hspi3.Init.NSSPMode = SPI_NSS_PULSE_DISABLE;
  hspi3.Init.NSSPolarity = SPI_NSS_POLARITY_LOW;
  hspi3.Init.FifoThreshold = SPI_FIFO_THRESHOLD_01DATA;
  hspi3.Init.MasterSSIdleness = SPI_MASTER_SS_IDLENESS_00CYCLE;
  hspi3.Init.MasterInterDataIdleness = SPI_MASTER_INTERDATA_IDLENESS_00CYCLE;
  hspi3.Init.MasterReceiverAutoSusp = SPI_MASTER_RX_AUTOSUSP_DISABLE;
  hspi3.Init.MasterKeepIOState = SPI_MASTER_KEEP_IO_STATE_DISABLE;
  hspi3.Init.IOSwap = SPI_IO_SWAP_DISABLE;
  hspi3.Init.ReadyMasterManagement = SPI_RDY_MASTER_MANAGEMENT_INTERNALLY;
  hspi3.Init.ReadyPolarity = SPI_RDY_POLARITY_HIGH;
  if (HAL_SPI_Init(&hspi3) != HAL_OK)
  {
    Error_Handler();
  }

}

static void MX_SPI4_Init(void)
{

  /* SPI4 parameter configuration*/
  hspi4.Instance = SPI4;
  hspi4.Init.Mode = SPI_MODE_MASTER;
  hspi4.Init.Direction = SPI_DIRECTION_2LINES;
  hspi4.Init.DataSize = SPI_DATASIZE_8BIT;
  hspi4.Init.CLKPolarity = SPI_POLARITY_LOW;
  hspi4.Init.CLKPhase = SPI_PHASE_1EDGE;
  hspi4.Init.NSS = SPI_NSS_SOFT;
  hspi4.Init.BaudRatePrescaler = SPI_BAUDRATEPRESCALER_32;
  hspi4.Init.FirstBit = SPI_FIRSTBIT_MSB;
  hspi4.Init.TIMode = SPI_TIMODE_DISABLE;
  hspi4.Init.CRCCalculation = SPI_CRCCALCULATION_DISABLE;
  hspi4.Init.CRCPolynomial = 0x7;
  hspi4.Init.NSSPMode = SPI_NSS_PULSE_ENABLE;
  hspi4.Init.NSSPolarity = SPI_NSS_POLARITY_LOW;
  hspi4.Init.FifoThreshold = SPI_FIFO_THRESHOLD_01DATA;
  hspi4.Init.MasterSSIdleness = SPI_MASTER_SS_IDLENESS_00CYCLE;
  hspi4.Init.MasterInterDataIdleness = SPI_MASTER_INTERDATA_IDLENESS_00CYCLE;
  hspi4.Init.MasterReceiverAutoSusp = SPI_MASTER_RX_AUTOSUSP_DISABLE;
  hspi4.Init.MasterKeepIOState = SPI_MASTER_KEEP_IO_STATE_DISABLE;
  hspi4.Init.IOSwap = SPI_IO_SWAP_DISABLE;
  hspi4.Init.ReadyMasterManagement = SPI_RDY_MASTER_MANAGEMENT_INTERNALLY;
  hspi4.Init.ReadyPolarity = SPI_RDY_POLARITY_HIGH;
  if (HAL_SPI_Init(&hspi4) != HAL_OK)
  {
    Error_Handler();
  }

}

static void MX_TIM1_Init(void)
{

  TIM_ClockConfigTypeDef sClockSourceConfig = {0};
  TIM_MasterConfigTypeDef sMasterConfig = {0};
  TIM_OC_InitTypeDef sConfigOC = {0};
  TIM_BreakDeadTimeConfigTypeDef sBreakDeadTimeConfig = {0};

  htim1.Instance = TIM1;
  htim1.Init.Prescaler = 0;
  htim1.Init.CounterMode = TIM_COUNTERMODE_UP;
  htim1.Init.Period = 255;
  htim1.Init.ClockDivision = TIM_CLOCKDIVISION_DIV1;
  htim1.Init.RepetitionCounter = 0;
  htim1.Init.AutoReloadPreload = TIM_AUTORELOAD_PRELOAD_DISABLE;
  if (HAL_TIM_Base_Init(&htim1) != HAL_OK)
  {
    Error_Handler();
  }
  sClockSourceConfig.ClockSource = TIM_CLOCKSOURCE_INTERNAL;
  if (HAL_TIM_ConfigClockSource(&htim1, &sClockSourceConfig) != HAL_OK)
  {
    Error_Handler();
  }
  if (HAL_TIM_PWM_Init(&htim1) != HAL_OK)
  {
    Error_Handler();
  }
  sMasterConfig.MasterOutputTrigger = TIM_TRGO_RESET;
  sMasterConfig.MasterOutputTrigger2 = TIM_TRGO2_RESET;
  sMasterConfig.MasterSlaveMode = TIM_MASTERSLAVEMODE_DISABLE;
  if (HAL_TIMEx_MasterConfigSynchronization(&htim1, &sMasterConfig) != HAL_OK)
  {
    Error_Handler();
  }
  sConfigOC.OCMode = TIM_OCMODE_PWM1;
  sConfigOC.Pulse = 0;
  sConfigOC.OCPolarity = TIM_OCPOLARITY_HIGH;
  sConfigOC.OCNPolarity = TIM_OCNPOLARITY_HIGH;
  sConfigOC.OCFastMode = TIM_OCFAST_DISABLE;
  sConfigOC.OCIdleState = TIM_OCIDLESTATE_RESET;
  sConfigOC.OCNIdleState = TIM_OCNIDLESTATE_RESET;
  if (HAL_TIM_PWM_ConfigChannel(&htim1, &sConfigOC, TIM_CHANNEL_1) != HAL_OK)
  {
    Error_Handler();
  }
  if (HAL_TIM_PWM_ConfigChannel(&htim1, &sConfigOC, TIM_CHANNEL_2) != HAL_OK)
  {
    Error_Handler();
  }
  if (HAL_TIM_PWM_ConfigChannel(&htim1, &sConfigOC, TIM_CHANNEL_3) != HAL_OK)
  {
    Error_Handler();
  }
  sBreakDeadTimeConfig.OffStateRunMode = TIM_OSSR_DISABLE;
  sBreakDeadTimeConfig.OffStateIDLEMode = TIM_OSSI_DISABLE;
  sBreakDeadTimeConfig.LockLevel = TIM_LOCKLEVEL_OFF;
  sBreakDeadTimeConfig.DeadTime = 0;
  sBreakDeadTimeConfig.BreakState = TIM_BREAK_DISABLE;
  sBreakDeadTimeConfig.BreakPolarity = TIM_BREAKPOLARITY_HIGH;
  sBreakDeadTimeConfig.BreakFilter = 0;
  sBreakDeadTimeConfig.BreakAFMode = TIM_BREAK_AFMODE_INPUT;
  sBreakDeadTimeConfig.Break2State = TIM_BREAK2_DISABLE;
  sBreakDeadTimeConfig.Break2Polarity = TIM_BREAK2POLARITY_HIGH;
  sBreakDeadTimeConfig.Break2Filter = 0;
  sBreakDeadTimeConfig.Break2AFMode = TIM_BREAK_AFMODE_INPUT;
  sBreakDeadTimeConfig.AutomaticOutput = TIM_AUTOMATICOUTPUT_DISABLE;
  if (HAL_TIMEx_ConfigBreakDeadTime(&htim1, &sBreakDeadTimeConfig) != HAL_OK)
  {
    Error_Handler();
  }
  HAL_TIM_MspPostInit(&htim1);

}

static void MX_TIM2_Init(void)
{

  TIM_ClockConfigTypeDef sClockSourceConfig = {0};
  TIM_MasterConfigTypeDef sMasterConfig = {0};
  TIM_OC_InitTypeDef sConfigOC = {0};

  htim2.Instance = TIM2;
  htim2.Init.Prescaler = 0;
  htim2.Init.CounterMode = TIM_COUNTERMODE_UP;
  htim2.Init.Period = 255;
  htim2.Init.ClockDivision = TIM_CLOCKDIVISION_DIV1;
  htim2.Init.AutoReloadPreload = TIM_AUTORELOAD_PRELOAD_DISABLE;
  if (HAL_TIM_Base_Init(&htim2) != HAL_OK)
  {
    Error_Handler();
  }
  sClockSourceConfig.ClockSource = TIM_CLOCKSOURCE_INTERNAL;
  if (HAL_TIM_ConfigClockSource(&htim2, &sClockSourceConfig) != HAL_OK)
  {
    Error_Handler();
  }
  if (HAL_TIM_PWM_Init(&htim2) != HAL_OK)
  {
    Error_Handler();
  }
  sMasterConfig.MasterOutputTrigger = TIM_TRGO_RESET;
  sMasterConfig.MasterSlaveMode = TIM_MASTERSLAVEMODE_DISABLE;
  if (HAL_TIMEx_MasterConfigSynchronization(&htim2, &sMasterConfig) != HAL_OK)
  {
    Error_Handler();
  }
  sConfigOC.OCMode = TIM_OCMODE_PWM1;
  sConfigOC.Pulse = 0;
  sConfigOC.OCPolarity = TIM_OCPOLARITY_HIGH;
  sConfigOC.OCFastMode = TIM_OCFAST_DISABLE;
  if (HAL_TIM_PWM_ConfigChannel(&htim2, &sConfigOC, TIM_CHANNEL_1) != HAL_OK)
  {
    Error_Handler();
  }
  if (HAL_TIM_PWM_ConfigChannel(&htim2, &sConfigOC, TIM_CHANNEL_2) != HAL_OK)
  {
    Error_Handler();
  }
  if (HAL_TIM_PWM_ConfigChannel(&htim2, &sConfigOC, TIM_CHANNEL_3) != HAL_OK)
  {
    Error_Handler();
  }
  HAL_TIM_MspPostInit(&htim2);

}

static void MX_TIM3_Init(void)
{

  TIM_ClockConfigTypeDef sClockSourceConfig = {0};
  TIM_MasterConfigTypeDef sMasterConfig = {0};
  TIM_OC_InitTypeDef sConfigOC = {0};

  htim3.Instance = TIM3;
  htim3.Init.Prescaler = 0;
  htim3.Init.CounterMode = TIM_COUNTERMODE_UP;
  htim3.Init.Period = 43939;
  htim3.Init.ClockDivision = TIM_CLOCKDIVISION_DIV1;
  htim3.Init.AutoReloadPreload = TIM_AUTORELOAD_PRELOAD_DISABLE;
  if (HAL_TIM_Base_Init(&htim3) != HAL_OK)
  {
    Error_Handler();
  }
  sClockSourceConfig.ClockSource = TIM_CLOCKSOURCE_INTERNAL;
  if (HAL_TIM_ConfigClockSource(&htim3, &sClockSourceConfig) != HAL_OK)
  {
    Error_Handler();
  }
  if (HAL_TIM_PWM_Init(&htim3) != HAL_OK)
  {
    Error_Handler();
  }
  sMasterConfig.MasterOutputTrigger = TIM_TRGO_RESET;
  sMasterConfig.MasterSlaveMode = TIM_MASTERSLAVEMODE_DISABLE;
  if (HAL_TIMEx_MasterConfigSynchronization(&htim3, &sMasterConfig) != HAL_OK)
  {
    Error_Handler();
  }
  sConfigOC.OCMode = TIM_OCMODE_PWM1;
  sConfigOC.Pulse = 0;
  sConfigOC.OCPolarity = TIM_OCPOLARITY_HIGH;
  sConfigOC.OCFastMode = TIM_OCFAST_DISABLE;
  if (HAL_TIM_PWM_ConfigChannel(&htim3, &sConfigOC, TIM_CHANNEL_2) != HAL_OK)
  {
    Error_Handler();
  }
  HAL_TIM_MspPostInit(&htim3);

}

static void MX_TIM6_Init(void)
{

  TIM_MasterConfigTypeDef sMasterConfig = {0};

  htim6.Instance = TIM6;
  htim6.Init.Prescaler = 1199;
  htim6.Init.CounterMode = TIM_COUNTERMODE_UP;
  htim6.Init.Period = 9999;
  htim6.Init.AutoReloadPreload = TIM_AUTORELOAD_PRELOAD_DISABLE;
  if (HAL_TIM_Base_Init(&htim6) != HAL_OK)
  {
    Error_Handler();
  }
  sMasterConfig.MasterOutputTrigger = TIM_TRGO_RESET;
  sMasterConfig.MasterSlaveMode = TIM_MASTERSLAVEMODE_DISABLE;
  if (HAL_TIMEx_MasterConfigSynchronization(&htim6, &sMasterConfig) != HAL_OK)
  {
    Error_Handler();
  }

}

static void MX_UART4_Init(void)
{

  huart4.Instance = UART4;
  huart4.Init.BaudRate = 9600;
  huart4.Init.WordLength = UART_WORDLENGTH_8B;
  huart4.Init.StopBits = UART_STOPBITS_1;
  huart4.Init.Parity = UART_PARITY_NONE;
  huart4.Init.Mode = UART_MODE_TX_RX;
  huart4.Init.HwFlowCtl = UART_HWCONTROL_NONE;
  huart4.Init.OverSampling = UART_OVERSAMPLING_16;
  huart4.Init.OneBitSampling = UART_ONE_BIT_SAMPLE_DISABLE;
  huart4.Init.ClockPrescaler = UART_PRESCALER_DIV1;
  huart4.AdvancedInit.AdvFeatureInit = UART_ADVFEATURE_NO_INIT;
  if (HAL_UART_Init(&huart4) != HAL_OK)
  {
    Error_Handler();
  }
  if (HAL_UARTEx_SetTxFifoThreshold(&huart4, UART_TXFIFO_THRESHOLD_1_8) != HAL_OK)
  {
    Error_Handler();
  }
  if (HAL_UARTEx_SetRxFifoThreshold(&huart4, UART_RXFIFO_THRESHOLD_1_8) != HAL_OK)
  {
    Error_Handler();
  }
  if (HAL_UARTEx_DisableFifoMode(&huart4) != HAL_OK)
  {
    Error_Handler();
  }

}

static void MX_UART5_Init(void)
{

  huart5.Instance = UART5;
  huart5.Init.BaudRate = 115200;
  huart5.Init.WordLength = UART_WORDLENGTH_8B;
  huart5.Init.StopBits = UART_STOPBITS_1;
  huart5.Init.Parity = UART_PARITY_NONE;
  huart5.Init.Mode = UART_MODE_TX_RX;
  huart5.Init.HwFlowCtl = UART_HWCONTROL_NONE;
  huart5.Init.OverSampling = UART_OVERSAMPLING_16;
  huart5.Init.OneBitSampling = UART_ONE_BIT_SAMPLE_DISABLE;
  huart5.Init.ClockPrescaler = UART_PRESCALER_DIV1;
  huart5.AdvancedInit.AdvFeatureInit = UART_ADVFEATURE_NO_INIT;
  if (HAL_UART_Init(&huart5) != HAL_OK)
  {
    Error_Handler();
  }
  if (HAL_UARTEx_SetTxFifoThreshold(&huart5, UART_TXFIFO_THRESHOLD_1_8) != HAL_OK)
  {
    Error_Handler();
  }
  if (HAL_UARTEx_SetRxFifoThreshold(&huart5, UART_RXFIFO_THRESHOLD_1_8) != HAL_OK)
  {
    Error_Handler();
  }
  if (HAL_UARTEx_DisableFifoMode(&huart5) != HAL_OK)
  {
    Error_Handler();
  }

}

static void MX_USB_PCD_Init(void)
{

  hpcd_USB_DRD_FS.Instance = USB_DRD_FS;
  hpcd_USB_DRD_FS.Init.dev_endpoints = 8;
  hpcd_USB_DRD_FS.Init.speed = USBD_FS_SPEED;
  hpcd_USB_DRD_FS.Init.phy_itface = PCD_PHY_EMBEDDED;
  hpcd_USB_DRD_FS.Init.Sof_enable = DISABLE;
  hpcd_USB_DRD_FS.Init.low_power_enable = DISABLE;
  hpcd_USB_DRD_FS.Init.lpm_enable = DISABLE;
  hpcd_USB_DRD_FS.Init.battery_charging_enable = DISABLE;
  hpcd_USB_DRD_FS.Init.vbus_sensing_enable = DISABLE;
  hpcd_USB_DRD_FS.Init.bulk_doublebuffer_enable = DISABLE;
  hpcd_USB_DRD_FS.Init.iso_singlebuffer_enable = DISABLE;
  if (HAL_PCD_Init(&hpcd_USB_DRD_FS) != HAL_OK)
  {
    Error_Handler();
  }

}

static void MX_GPIO_Init(void)
{
  GPIO_InitTypeDef GPIO_InitStruct = {0};
  /* USER CODE BEGIN MX_GPIO_Init_1 */
  __HAL_RCC_SBS_CLK_ENABLE();

  /* USER CODE END MX_GPIO_Init_1 */

  /* GPIO Ports Clock Enable */
  __HAL_RCC_GPIOE_CLK_ENABLE();
  __HAL_RCC_GPIOC_CLK_ENABLE();
  __HAL_RCC_GPIOH_CLK_ENABLE();
  __HAL_RCC_GPIOA_CLK_ENABLE();
  __HAL_RCC_GPIOB_CLK_ENABLE();
  __HAL_RCC_GPIOD_CLK_ENABLE();

  /*Configure GPIO pin Output Level */
  HAL_GPIO_WritePin(GPIOE, SENSE_2_Pin|PYRO_1_Pin|SENSE_3_Pin|RF_TXEN_Pin
                          |RF_RXEN_Pin|RF_RESET_Pin|RF_CS_Pin, GPIO_PIN_RESET);

  /*Configure GPIO pin Output Level */
  HAL_GPIO_WritePin(GPIOC, PYRO_4_Pin|RF_DIO3_Pin|RF_DIO2_Pin, GPIO_PIN_RESET);

  /*Configure GPIO pin Output Level */
  HAL_GPIO_WritePin(BARO_CS_GPIO_Port, BARO_CS_Pin, GPIO_PIN_RESET);

  /*Configure GPIO pin Output Level */
  HAL_GPIO_WritePin(GPIOD, IMU_CS_Pin|GPS_RESET_Pin, GPIO_PIN_RESET);

  /*Configure GPIO pin Output Level */
  HAL_GPIO_WritePin(MAG_CS_GPIO_Port, MAG_CS_Pin, GPIO_PIN_RESET);

  /*Configure GPIO pins : SENSE_2_Pin PYRO_1_Pin SENSE_3_Pin RF_TXEN_Pin
                           RF_RXEN_Pin RF_RESET_Pin */
  GPIO_InitStruct.Pin = SENSE_2_Pin|PYRO_1_Pin|SENSE_3_Pin|RF_TXEN_Pin
                          |RF_RXEN_Pin|RF_RESET_Pin;
  GPIO_InitStruct.Mode = GPIO_MODE_OUTPUT_PP;
  GPIO_InitStruct.Pull = GPIO_NOPULL;
  GPIO_InitStruct.Speed = GPIO_SPEED_FREQ_LOW;
  HAL_GPIO_Init(GPIOE, &GPIO_InitStruct);

  /*Configure GPIO pins : PYRO_2_Pin SENSE_1_Pin */
  GPIO_InitStruct.Pin = PYRO_2_Pin|SENSE_1_Pin;
  GPIO_InitStruct.Mode = GPIO_MODE_INPUT;
  GPIO_InitStruct.Pull = GPIO_NOPULL;
  HAL_GPIO_Init(GPIOE, &GPIO_InitStruct);

  /*Configure GPIO pins : PYRO_3_Pin SENSE_4_Pin */
  GPIO_InitStruct.Pin = PYRO_3_Pin|SENSE_4_Pin;
  GPIO_InitStruct.Mode = GPIO_MODE_INPUT;
  GPIO_InitStruct.Pull = GPIO_NOPULL;
  HAL_GPIO_Init(GPIOC, &GPIO_InitStruct);

  /*Configure GPIO pins : PYRO_4_Pin RF_DIO3_Pin RF_DIO2_Pin */
  GPIO_InitStruct.Pin = PYRO_4_Pin|RF_DIO3_Pin|RF_DIO2_Pin;
  GPIO_InitStruct.Mode = GPIO_MODE_OUTPUT_PP;
  GPIO_InitStruct.Pull = GPIO_NOPULL;
  GPIO_InitStruct.Speed = GPIO_SPEED_FREQ_LOW;
  HAL_GPIO_Init(GPIOC, &GPIO_InitStruct);

  /*Configure GPIO pin : LM660_ST_Pin */
  GPIO_InitStruct.Pin = LM660_ST_Pin;
  GPIO_InitStruct.Mode = GPIO_MODE_INPUT;
  GPIO_InitStruct.Pull = GPIO_NOPULL;
  HAL_GPIO_Init(LM660_ST_GPIO_Port, &GPIO_InitStruct);

  /*Configure GPIO pins : RF_DIO1_Pin MAG_INT_Pin */
  GPIO_InitStruct.Pin = RF_DIO1_Pin|MAG_INT_Pin;
  GPIO_InitStruct.Mode = GPIO_MODE_IT_RISING;
  GPIO_InitStruct.Pull = GPIO_NOPULL;
  HAL_GPIO_Init(GPIOE, &GPIO_InitStruct);

  /*Configure GPIO pin : RF_CS_Pin */
  GPIO_InitStruct.Pin = RF_CS_Pin;
  GPIO_InitStruct.Mode = GPIO_MODE_OUTPUT_PP;
  GPIO_InitStruct.Pull = GPIO_PULLUP;
  GPIO_InitStruct.Speed = GPIO_SPEED_FREQ_LOW;
  HAL_GPIO_Init(RF_CS_GPIO_Port, &GPIO_InitStruct);

  /*Configure GPIO pin : RF_BUSY_Pin */
  GPIO_InitStruct.Pin = RF_BUSY_Pin;
  GPIO_InitStruct.Mode = GPIO_MODE_INPUT;
  GPIO_InitStruct.Pull = GPIO_PULLDOWN;
  HAL_GPIO_Init(RF_BUSY_GPIO_Port, &GPIO_InitStruct);

  /*Configure GPIO pin : BARO_CS_Pin */
  GPIO_InitStruct.Pin = BARO_CS_Pin;
  GPIO_InitStruct.Mode = GPIO_MODE_OUTPUT_PP;
  GPIO_InitStruct.Pull = GPIO_PULLUP;
  GPIO_InitStruct.Speed = GPIO_SPEED_FREQ_LOW;
  HAL_GPIO_Init(BARO_CS_GPIO_Port, &GPIO_InitStruct);

  /*Configure GPIO pin : IMU_CS_Pin */
  GPIO_InitStruct.Pin = IMU_CS_Pin;
  GPIO_InitStruct.Mode = GPIO_MODE_OUTPUT_PP;
  GPIO_InitStruct.Pull = GPIO_PULLUP;
  GPIO_InitStruct.Speed = GPIO_SPEED_FREQ_LOW;
  HAL_GPIO_Init(IMU_CS_GPIO_Port, &GPIO_InitStruct);

  /*Configure GPIO pins : IMU_INT2_Pin IMU_INT1_Pin BTN_3_Pin BTN_2_Pin
                           BTN_1_Pin */
  GPIO_InitStruct.Pin = IMU_INT2_Pin|IMU_INT1_Pin|BTN_3_Pin|BTN_2_Pin
                          |BTN_1_Pin;
  GPIO_InitStruct.Mode = GPIO_MODE_IT_RISING;
  GPIO_InitStruct.Pull = GPIO_PULLDOWN;
  HAL_GPIO_Init(GPIOD, &GPIO_InitStruct);

  /*Configure GPIO pins : BARO_INT_Pin GPS_TP_Pin */
  GPIO_InitStruct.Pin = BARO_INT_Pin|GPS_TP_Pin;
  GPIO_InitStruct.Mode = GPIO_MODE_IT_RISING;
  GPIO_InitStruct.Pull = GPIO_NOPULL;
  HAL_GPIO_Init(GPIOD, &GPIO_InitStruct);

  /*Configure GPIO pin : GPS_RESET_Pin */
  GPIO_InitStruct.Pin = GPS_RESET_Pin;
  GPIO_InitStruct.Mode = GPIO_MODE_OUTPUT_PP;
  GPIO_InitStruct.Pull = GPIO_NOPULL;
  GPIO_InitStruct.Speed = GPIO_SPEED_FREQ_LOW;
  HAL_GPIO_Init(GPS_RESET_GPIO_Port, &GPIO_InitStruct);

  /*Configure GPIO pin : GPS_EXTI_Pin */
  GPIO_InitStruct.Pin = GPS_EXTI_Pin;
  GPIO_InitStruct.Mode = GPIO_MODE_IT_RISING;
  GPIO_InitStruct.Pull = GPIO_NOPULL;
  HAL_GPIO_Init(GPS_EXTI_GPIO_Port, &GPIO_InitStruct);

  /*Configure GPIO pins : PC8 PC9 PC10 PC11
                           PC12 */
  GPIO_InitStruct.Pin = GPIO_PIN_8|GPIO_PIN_9|GPIO_PIN_10|GPIO_PIN_11
                          |GPIO_PIN_12;
  GPIO_InitStruct.Mode = GPIO_MODE_AF_PP;
  GPIO_InitStruct.Pull = GPIO_NOPULL;
  GPIO_InitStruct.Speed = GPIO_SPEED_FREQ_VERY_HIGH;
  GPIO_InitStruct.Alternate = GPIO_AF12_SDMMC1;
  HAL_GPIO_Init(GPIOC, &GPIO_InitStruct);

  /*Configure GPIO pin : MAG_CS_Pin */
  GPIO_InitStruct.Pin = MAG_CS_Pin;
  GPIO_InitStruct.Mode = GPIO_MODE_OUTPUT_PP;
  GPIO_InitStruct.Pull = GPIO_PULLUP;
  GPIO_InitStruct.Speed = GPIO_SPEED_FREQ_LOW;
  HAL_GPIO_Init(MAG_CS_GPIO_Port, &GPIO_InitStruct);

  /*Configure GPIO pin : SD_DET_Pin */
  GPIO_InitStruct.Pin = SD_DET_Pin;
  GPIO_InitStruct.Mode = GPIO_MODE_INPUT;
  GPIO_InitStruct.Pull = GPIO_NOPULL;
  HAL_GPIO_Init(SD_DET_GPIO_Port, &GPIO_InitStruct);

  /*Configure GPIO pin : PD2 */
  GPIO_InitStruct.Pin = GPIO_PIN_2;
  GPIO_InitStruct.Mode = GPIO_MODE_AF_PP;
  GPIO_InitStruct.Pull = GPIO_NOPULL;
  GPIO_InitStruct.Speed = GPIO_SPEED_FREQ_VERY_HIGH;
  GPIO_InitStruct.Alternate = GPIO_AF12_SDMMC1;
  HAL_GPIO_Init(GPIOD, &GPIO_InitStruct);

  /* EXTI interrupt init*/
  HAL_NVIC_SetPriority(EXTI3_IRQn, 0, 0);
  HAL_NVIC_EnableIRQ(EXTI3_IRQn);

  HAL_NVIC_SetPriority(EXTI4_IRQn, 0, 0);
  HAL_NVIC_EnableIRQ(EXTI4_IRQn);

  HAL_NVIC_SetPriority(EXTI5_IRQn, 0, 0);
  HAL_NVIC_EnableIRQ(EXTI5_IRQn);

  HAL_NVIC_SetPriority(EXTI7_IRQn, 0, 0);
  HAL_NVIC_EnableIRQ(EXTI7_IRQn);

  HAL_NVIC_SetPriority(EXTI9_IRQn, 0, 0);
  HAL_NVIC_EnableIRQ(EXTI9_IRQn);

  HAL_NVIC_SetPriority(EXTI10_IRQn, 0, 0);
  HAL_NVIC_EnableIRQ(EXTI10_IRQn);

  HAL_NVIC_SetPriority(EXTI13_IRQn, 0, 0);
  HAL_NVIC_EnableIRQ(EXTI13_IRQn);

}

/* USER CODE BEGIN 4 */
/**
  * @brief  Retargets the C library printf function to the USART.
  *   None
  * @retval None
  */
PUTCHAR_PROTOTYPE
{
  /* Place your implementation of fputc here */
  /* e.g. write a character to the USART1 and Loop until the end of transmission */
  HAL_UART_Transmit(&huart5, (uint8_t *)&ch, 1, 0xFFFF);

  return ch;
}

int baro_flag;
int imu_flag;

void HAL_GPIO_EXTI_Callback(uint16_t GPIO_Pin)
{

	if (GPIO_Pin == BARO_INT_Pin) {
		baro_int_drdy_handler();
		baro_flag = 1;
	}
	 else if(GPIO_Pin == IMU_INT1_Pin || GPIO_Pin == IMU_INT2_Pin) {
		imu_int_drdy_handler();
		imu_flag = 1;
	} else if(GPIO_Pin == MAG_INT_Pin) {
		mag_int_drdy_handler();
	}
		else if(GPIO_Pin == RF_DIO1_Pin){

	sx126x_irq_process(&radio);

	}

}

void mode_current_handler(uint8_t mode){

	//define mode handling functions
	void mode_current_handler(uint8_t mode)
	{ //define all the modes

	    if (mode == STARTUP){

	    } else if (mode == IDLE){

	    } else if (mode == LAUNCH_DETECT){

	    } else if (mode == ASCENT){

	    } else if (mode == DESCENT){

	    }else if (mode == LANDED){

	    }else if (mode == TEST_SENSORS){

	    }else if (mode == TEST_LORA){

	    }else if (mode == TEST_TELEMETRY){

	    }else if (mode == TEST_UI){

	    }else if (mode == TEST_FLASH){

	    } else if (mode == TEST_GPS){

	    }

	}

}

void mode_transition_handler(uint8_t mode_prev, uint8_t mode_current){

}

void determine_rocket_state(state_t current_state){

	//need to make ascent, decsent, landed
	if ((current_state.is_launched == 0) && (current_state.apogee_detect == 0) && (current_state.land_detect == 0)){
		current_state.state = ASCENT;
	} else if ((current_state.is_launched == 1) && (current_state.apogee_detect == 1) && (current_state.land_detect == 0)){
		current_state.state = DESCENT;
	} else if ((current_state.is_launched == 1) && (current_state.apogee_detect == 1) && (current_state.land_detect == 0)){
		current_state.state = LANDED;
	}

}

void HAL_SPI_TxRxCpltCallback(SPI_HandleTypeDef *hspi)
{
	if (hspi->Instance == SPI2) {

//		baro_spi_callback();
//		baro_flag = 0;
//		} else if (imu_flag == 1) {
		imu_spi_callback();
//		imu_flag = 0;

// TODO add imu here
	}
}

void HAL_SPI_RxCpltCallback(SPI_HandleTypeDef *hspi) {
	if (hspi->Instance == SPI3) {
		mag_spi_callback();
	}
}

void HAL_TIM_PeriodElapsedCallback(TIM_HandleTypeDef *htim) {
	if (htim->Instance == TIM6) { // 100 Hz
			tick_100Hz = 1;
		}
}

/* USER CODE END 4 */

void Error_Handler(void)
{
  __disable_irq();
  while (1)
  {
  }
}
